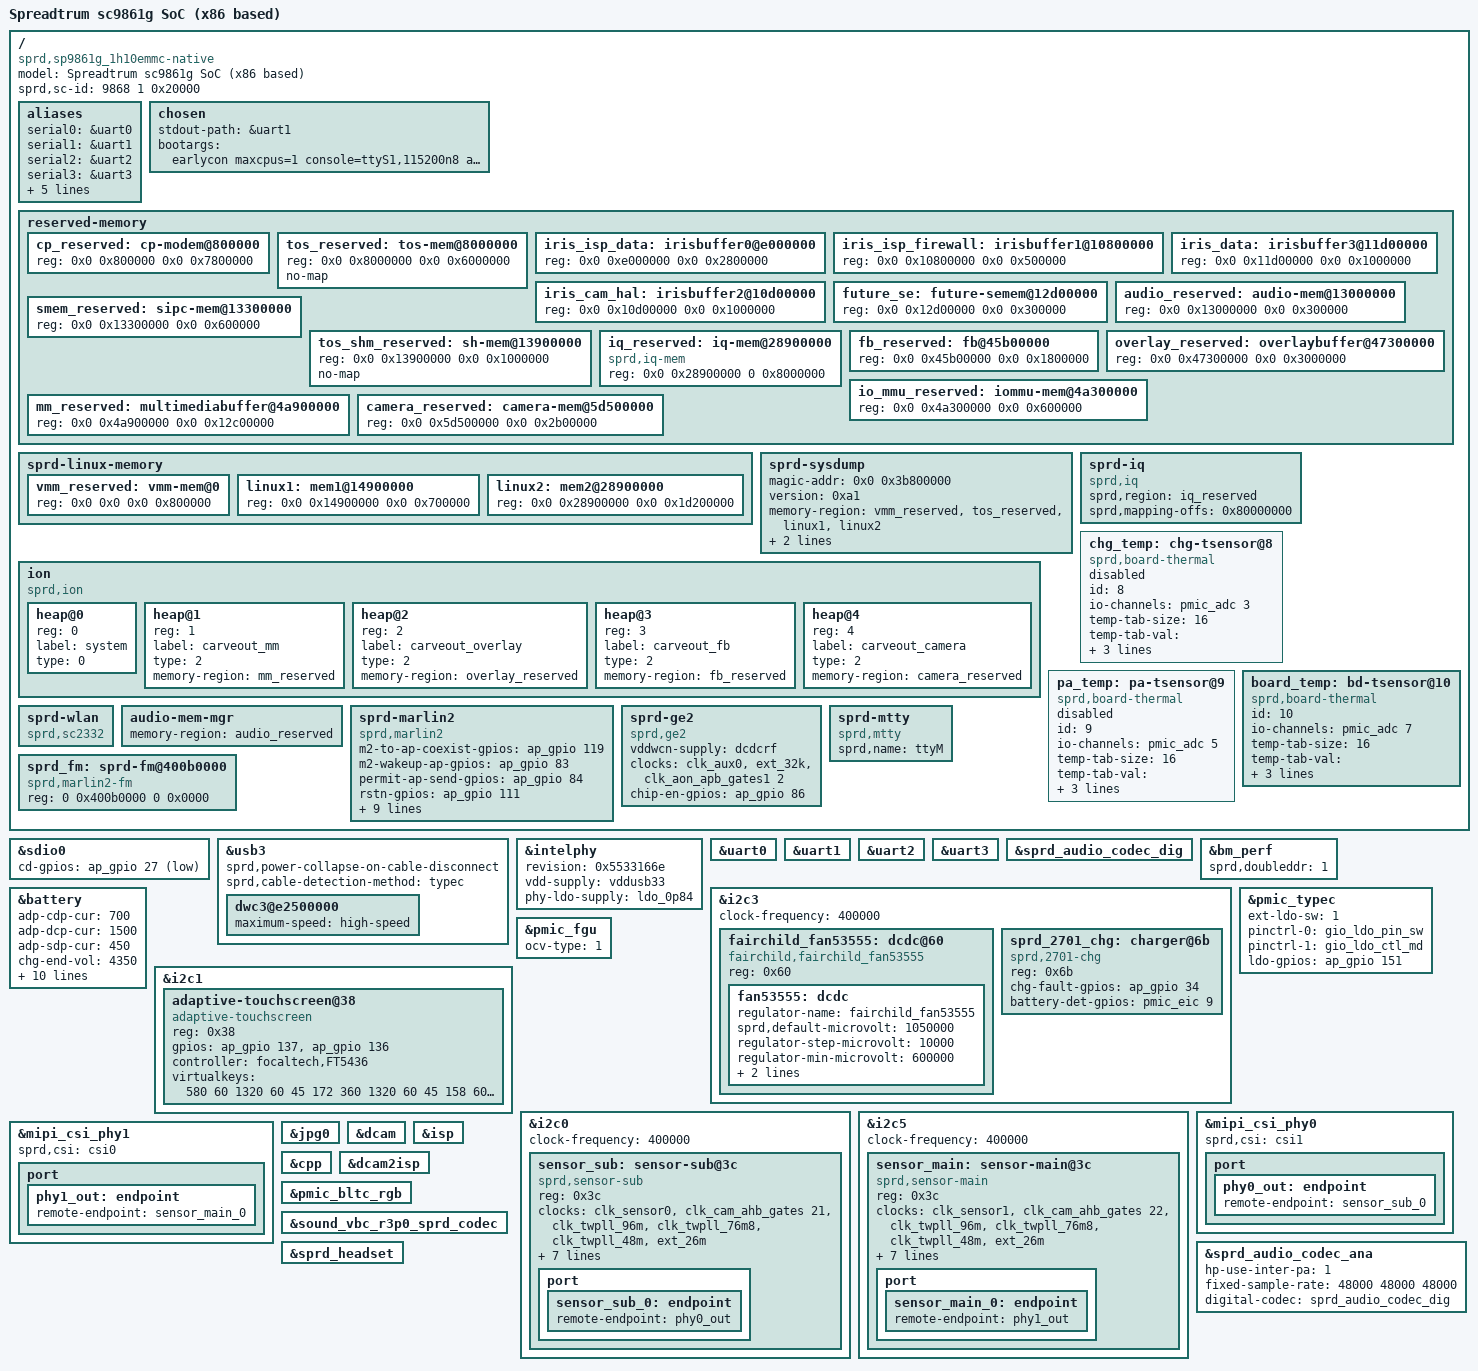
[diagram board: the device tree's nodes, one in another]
/*
 * Spreadtrum iwhale2 fpga board DTS file
 *
 * Copyright (C) 2015, Spreadtrum Communications Inc.
 *
 * This file is licensed under a dual GPLv2 or X11 license.
 */

/dts-v1/;
#include "irq-hw-sc9861.h"
#include "bia.dtsi"
#include "sc9861.dtsi"
#include "sc9861-modem.dtsi"
#include "sp9861-common.dtsi"
#include "sprd-sound.dtsi"

/ {
	model = "Spreadtrum sc9861g SoC (x86 based)";

	compatible = "sprd,sp9861g_1h10emmc-native";

	sprd,sc-id = <9868 1 0x20000>;

	aliases {
		serial0 = &uart0;
		serial1 = &uart1;
		serial2 = &uart2;
		serial3 = &uart3;
		i2c0 = &i2c0;
		i2c1 = &i2c1;
		i2c3 = &i2c3;
		i2c4 = &i2c4;
		i2c5 = &i2c5;
	};

	chosen {
		stdout-path = &uart1;
		bootargs = "earlycon maxcpus=1 console=ttyS1,115200n8 androidboot.hardware=sp9861g_1h10emmc  loglevel=11 code_bytes=128";
	};

	reserved-memory {
		#address-cells = <2>;
		#size-cells = <2>;
		ranges;

		cp_reserved: cp-modem@800000 {
			reg = <0x0 0x800000 0x0 0x7800000>;
		};

		tos_reserved: tos-mem@8000000  {
			reg = <0x0 0x8000000 0x0 0x6000000>;
			no-map;
		};

		iris_isp_data: irisbuffer0@e000000 {
			reg = <0x0 0xe000000 0x0 0x2800000>;
		};

		iris_isp_firewall: irisbuffer1@10800000 {
			reg = <0x0 0x10800000 0x0 0x500000>;
		};

		iris_cam_hal: irisbuffer2@10d00000 {
			reg = <0x0 0x10d00000 0x0 0x1000000>;
		};

		iris_data: irisbuffer3@11d00000 {
			reg = <0x0 0x11d00000 0x0 0x1000000>;
		};

		/* future security used */
		future_se: future-semem@12d00000 {
			reg = <0x0 0x12d00000 0x0 0x300000>;
		};

		audio_reserved: audio-mem@13000000 {
			reg = <0x0 0x13000000 0x0 0x300000>;
		};

		smem_reserved: sipc-mem@13300000 {
			reg = <0x0 0x13300000 0x0 0x600000>;
		};

		tos_shm_reserved: sh-mem@13900000 {
			reg = <0x0 0x13900000 0x0 0x1000000>;
			no-map;
		};

		/* used for iq capture, will be removed in normal mode */
		iq_reserved: iq-mem@28900000{
			compatible = "sprd,iq-mem";
			reg = <0x0 0x28900000 0 0x8000000>;
		};

		/* fb */
		fb_reserved: fb@45b00000 {
			reg = <0x0 0x45b00000 0x0 0x1800000>;
		};

		overlay_reserved: overlaybuffer@47300000 {
			reg = <0x0 0x47300000 0x0 0x3000000>;
		};

		io_mmu_reserved: iommu-mem@4a300000 {
			reg = <0x0 0x4a300000 0x0 0x600000>;
		};

		/* camera multi-layer mode capture */
		mm_reserved: multimediabuffer@4a900000 {
			reg = <0x0 0x4a900000 0x0 0x12c00000>;
		};

		camera_reserved: camera-mem@5d500000 {
			reg = <0x0 0x5d500000 0x0 0x2b00000>;
		};
	};

	sprd-linux-memory {
		#address-cells = <2>;
		#size-cells = <2>;
		ranges;

		vmm_reserved: vmm-mem@0 {
			reg = <0x0 0x0 0x0 0x800000>;
		};

		linux1: mem1@14900000 {
			reg = <0x0 0x14900000 0x0 0x700000>;
		};

		linux2: mem2@28900000 {
			reg = <0x0 0x28900000 0x0 0x1d200000>;
		};
	};

	sprd-sysdump {
		#address-cells = <2>;
		magic-addr = <0x0 0x3b800000>;

		version = <0xa1>;

		memory-region = <&vmm_reserved>, <&tos_reserved>, <&linux1>, <&linux2>;
		memory-region-se = <&tos_reserved>;
		memory-region-re = <&cp_reserved>, <&smem_reserved>;
	};

	ion {
		compatible = "sprd,ion";
		#address-cells = <1>;
		#size-cells = <0>;

		heap@0 {
			reg = <0>;
			label = "system";
			type = <0>;
		};

		heap@1 {
			reg = <1>;
			label = "carveout_mm";
			type = <2>;
			memory-region = <&mm_reserved>;
		};

		heap@2 {
			reg = <2>;
			label = "carveout_overlay";
			type = <2>;
			memory-region = <&overlay_reserved>;
		};

		heap@3 {
			reg = <3>;
			label = "carveout_fb";
			type = <2>;
			memory-region = <&fb_reserved>;
		};

		heap@4 {
			reg = <4>;
			label = "carveout_camera";
			type = <2>;
			memory-region = <&camera_reserved>;
		};
	};

	sprd-iq {
		compatible = "sprd,iq";
		sprd,region = <&iq_reserved>;
		sprd,mapping-offs = <0x80000000>;
	};

	chg_temp:chg-tsensor@8 {
		compatible = "sprd,board-thermal";
		#thermal-sensor-cells = <1>;
		id = <8>;
		io-channels = <&pmic_adc 3>;
		io-channel-names = "adc_temp";
		temp-tab-size = <16>;
		temp-tab-val = <1140 1132 1109 1074 983 838 654 413
				316 238 178 133 99 75 57 43>;
		temp-tab-temp = <558 596 704 806 953 1101 1248 1450
				1549 1649 1749 1849 1951 2049 2148 2252>;
	};

	pa_temp:pa-tsensor@9 {
		compatible = "sprd,board-thermal";
		#thermal-sensor-cells = <1>;
		id = <9>;
		io-channels = <&pmic_adc 5>;
		io-channel-names = "adc_temp";
		temp-tab-size = <16>;
		temp-tab-val = <1140 1132 1109 1074 983 838 654 413
				316 238 178 133 99 75 57 43>;
		temp-tab-temp = <558 596 704 806 953 1101 1248 1450
				1549 1649 1749 1849 1951 2049 2148 2252>;
	};

	board_temp:bd-tsensor@10 {
		compatible = "sprd,board-thermal";
		#thermal-sensor-cells = <1>;
		id = <10>;
		io-channels = <&pmic_adc 7>;
		io-channel-names = "adc_temp";
		temp-tab-size = <16>;
		temp-tab-val = <1140 1132 1109 1074 983 838 654 413
				316 238 178 133 99 75 57 43>;
		temp-tab-temp = <558 596 704 806 953 1101 1248 1450
				1549 1649 1749 1849 1951 2049 2148 2252>;
	};

	sprd-wlan {
		compatible = "sprd,sc2332";
	};

	audio-mem-mgr {
		memory-region = <&audio_reserved>;
	};

	sprd-marlin2 {
		compatible = "sprd,marlin2";
		m2-to-ap-coexist-gpios = <&ap_gpio 119 0>;
		m2-wakeup-ap-gpios = <&ap_gpio 83 0>;
		permit-ap-send-gpios = <&ap_gpio 84 0>;
		rstn-gpios = <&ap_gpio 111 0>;
		chip-en-gpios = <&ap_gpio 86 0>;
		m2-to-ap-irq-gpios = <&ap_gpio 113 0>;
		vddwcn-supply = <&dcdcrf>;
		vdd_marlin2_1v2-supply = <&vddsram>;
		clock-names = "clk_32k","source","enable";
		clocks = <&clk_aux0>,<&ext_32k>,
			 <&clk_aon_apb_gates1 2>;
		sdhci-name = <&sdio1>;
		common_chip_en;
		power-ctl-disabled;
	};

	sprd-ge2 {
		compatible = "sprd,ge2";
		vddwcn-supply = <&dcdcrf>;
		clock-names = "clk_32k","source","enable";
		clocks = <&clk_aux0>,<&ext_32k>,
			 <&clk_aon_apb_gates1 2>;
		chip-en-gpios = <&ap_gpio 86 0>;
	};

	sprd-mtty {
		compatible = "sprd,mtty";
		sprd,name = "ttyM";
	};

	sprd_fm: sprd-fm@400b0000{
		compatible  = "sprd,marlin2-fm";
		reg = <0 0x400b0000 0 0x0000>;
	};
};

&sdio0 {
	cd-gpios = <&ap_gpio 27 1>;
};

&usb3 {
	status = "okay";
	sprd,power-collapse-on-cable-disconnect;

	/* usb cable detection method may be one of the three:
	 * "typec","gpios","none"
	 */
	sprd,cable-detection-method = "typec";
	dwc3@e2500000 {
		/* super-speed, high-speed, full-speed and etc. */
		maximum-speed = "high-speed";
	};
};

&intelphy {
	status = "okay";
	/* 0x5533286e - USB3_PHY_TSMC_28nm; 0x5533166e - USB3_PHY_TMSC_16nm */
	revision = <0x5533166e>;
	vdd-supply = <&vddusb33>;
	phy-ldo-supply = <&ldo_0p84>;
};

&uart0 {
	status = "okay";
};

&uart1 {
	status = "okay";
};

&uart2 {
	status = "okay";
};

&uart3 {
	status = "okay";
};

&sprd_audio_codec_dig {
	status = "okay";
};

&bm_perf {
	sprd,doubleddr = <1>;
};

&i2c3 {
	status = "okay";
	clock-frequency = <400000>;

	fairchild_fan53555: dcdc@60{
		compatible = "fairchild,fairchild_fan53555";
		reg = <0x60>;

		fan53555: dcdc {
			regulator-name = "fairchild_fan53555";
			sprd,default-microvolt = <1050000>;
			regulator-step-microvolt = <10000>;
			regulator-min-microvolt = <600000>;
			regulator-max-microvolt = <1230000>;
			enable-gpios = <&ap_gpio 163 0>;
		};
	};

	sprd_2701_chg: charger@6b {
	       compatible = "sprd,2701-chg";
	       reg = <0x6b>;
	       chg-fault-gpios = <&ap_gpio 34 0>;
	       battery-det-gpios = <&pmic_eic 9 0>;
	};
};

&battery {
	adp-cdp-cur = <700>;
	adp-dcp-cur = <1500>;
	adp-sdp-cur = <450>;
	chg-end-vol = <4350>;
	chg-end-vol-check = <4330>;
	chg-bat-safety-vol = <4430>;
	rechg-vol = <4270>;
	rsense-real = <100>;
	rint = <320>;
	cnom = <2780>;
	ocv-tab-vol = <4360 4249 4189 4133 4081 4034 3991
			3953 3910 3866 3836 3813 3795 3782
			3774 3765 3750 3726 3687 3658 3400>;
	ocv-tab-cap = <100  95   90   85   80   75   70
			65   60   55   50   45   40   35
			30   25   20   15   10   5    0>;
};

&pmic_typec {
	ext-ldo-sw = <1>;
	pinctrl-names = "ldo_pin_sw","ldo_ctl_md";
	pinctrl-0 = <&gio_ldo_pin_sw>;
	pinctrl-1 = <&gio_ldo_ctl_md>;
	ldo-gpios = <&ap_gpio 151 0>;
	status = "okay";
};

&pmic_fgu {
	ocv-type = <1>;
};

&i2c1 {
	status = "okay";
	adaptive-touchscreen@38 {
		compatible = "adaptive-touchscreen";
		reg = <0x38>;
		gpios = <&ap_gpio 137 0
			&ap_gpio 136 0>;
		controller = "focaltech,FT5436";
		virtualkeys = <580 60 1320 60 45
				172 360 1320 60 45
				158 600 1320 60 45>;
	};
};

&i2c0 {
	status = "okay";
	clock-frequency = <400000>;

	sensor_sub: sensor-sub@3c {
		compatible = "sprd,sensor-sub";
		reg = <0x3c>;
		clock-names = "clk_src","sensor_eb",
			"clk_96m","clk_76m8",
			"clk_48m","clk_26m";
		clocks = <&clk_sensor0>,<&clk_cam_ahb_gates 21>,
			<&clk_twpll_96m>,<&clk_twpll_76m8>,
			<&clk_twpll_48m>,<&ext_26m>;
		vddio-supply = <&vddcamio>;
		vddcama-supply = <&vddcama1>;
		vddcamd-supply = <&vddcamd1>;
		vddcammot-supply = <&vddcammot>;
		reset-gpios = <&ap_gpio 123 0>;
		power-down-gpios = <&ap_gpio 124 0>;
		host = "dcam1";
		port {
			sensor_sub_0: endpoint {
				remote-endpoint = <&phy0_out>;
			};
		};
	};
};

&i2c5 {
	status = "okay";
	clock-frequency = <400000>;

	sensor_main: sensor-main@3c {
		compatible = "sprd,sensor-main";
		reg = <0x3c>;
		clock-names = "clk_src","sensor_eb",
			"clk_96m","clk_76m8",
			"clk_48m","clk_26m";
		clocks = <&clk_sensor1>,<&clk_cam_ahb_gates 22>,
			<&clk_twpll_96m>,<&clk_twpll_76m8>,
			<&clk_twpll_48m>,<&ext_26m>;
		vddio-supply = <&vddcamio>;
		vddcama-supply = <&vddcama0>;
		vddcamd-supply = <&vddcamd0>;
		vddcammot-supply = <&vddcammot>;
		reset-gpios = <&ap_gpio 157 0>;
		power-down-gpios = <&ap_gpio 125 0>;
		host = "dcam0";
		port {
			sensor_main_0: endpoint {
				remote-endpoint = <&phy1_out>;
			};
		};
	};
};

&mipi_csi_phy0 {
	status = "okay";

	sprd,csi = <&csi1>;
	port {
		phy0_out: endpoint {
			remote-endpoint = <&sensor_sub_0>;
		};
	};
};

&mipi_csi_phy1 {
	status = "okay";

	sprd,csi = <&csi0>;
	port {
		phy1_out: endpoint {
			remote-endpoint = <&sensor_main_0>;
		};
	};
};

&sprd_audio_codec_ana {
	status = "okay";
	hp-use-inter-pa = <1>;
	fixed-sample-rate = <48000 48000 48000>; /* DA, AD, AD1 */
	digital-codec = <&sprd_audio_codec_dig>;
};

&jpg0 {
	status = "okay";
};

&dcam {
	status = "okay";
};

&isp {
	status = "okay";
};

&cpp {
	status = "okay";
};

&dcam2isp {
	status = "okay";
};
&pmic_bltc_rgb {
	status = "okay";
};

&sound_vbc_r3p0_sprd_codec {
	status = "okay";
};

&sprd_headset {
	status = "okay";
};

&chg_temp {
	status = "disabled";
};

&pa_temp {
	status = "disabled";
};
